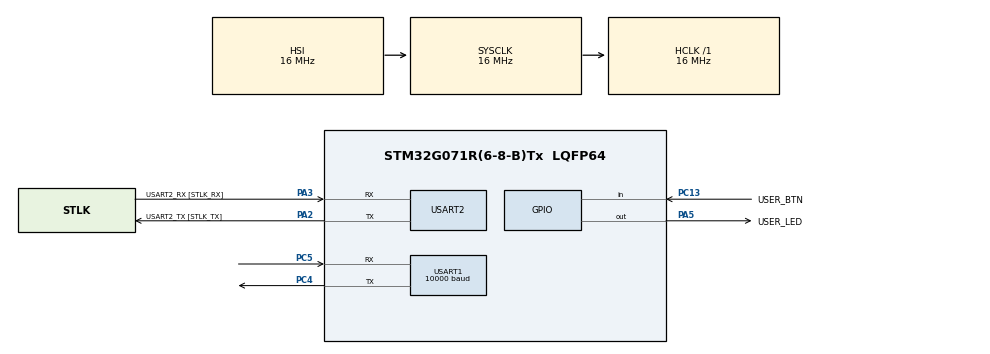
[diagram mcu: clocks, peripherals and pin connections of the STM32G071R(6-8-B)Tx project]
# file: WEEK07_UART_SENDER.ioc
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Mcu.Family=STM32G0
Mcu.Name=STM32G071R(6-8-B)Tx
Mcu.Package=LQFP64
PA13.GPIO_Label=TMS
PA13.Mode=Serial_Wire
PA13.Signal=SYS_SWDIO
PA14-BOOT0.GPIO_Label=TCK
PA14-BOOT0.Mode=Serial_Wire
PA14-BOOT0.Signal=SYS_SWCLK
PA2.GPIO_Label=USART2_TX [STLK_TX]
PA2.GPIO_PuPd=GPIO_PULLUP
PA2.Mode=Asynchronous
PA2.Signal=USART2_TX
PA3.GPIO_Label=USART2_RX [STLK_RX]
PA3.GPIO_PuPd=GPIO_PULLUP
PA3.Mode=Asynchronous
PA3.Signal=USART2_RX
PA5.GPIO_Label=USER_LED
PA5.GPIO_Speed=GPIO_SPEED_FREQ_HIGH
PA5.Signal=GPIO_Output
PC13.GPIO_Label=USER_BTN
PC13.Signal=GPIO_Input
PC14-OSC32_IN\ (PC14).Mode=LSE-External-Oscillator
PC14-OSC32_IN\ (PC14).Signal=RCC_OSC32_IN
PC15-OSC32_OUT\ (PC15).Mode=LSE-External-Oscillator
PC15-OSC32_OUT\ (PC15).Signal=RCC_OSC32_OUT
PC4.Mode=Asynchronous
PC4.Signal=USART1_TX
PC5.Mode=Asynchronous
PC5.Signal=USART1_RX
PF0-OSC_IN\ (PF0).GPIO_Label=MCO
PF0-OSC_IN\ (PF0).Mode=HSE-External-Clock-Source
PF0-OSC_IN\ (PF0).Signal=RCC_OSC_IN
ProjectManager.HeapSize=0x200
ProjectManager.StackSize=0x400
ProjectManager.TargetToolchain=STM32CubeIDE
RCC.AHBFreq_Value=16000000
RCC.CortexFreq_Value=16000000
RCC.EXTERNAL_CLOCK_VALUE=12288000
RCC.HCLKFreq_Value=16000000
RCC.HSE_VALUE=8000000
RCC.HSI_VALUE=16000000
RCC.SYSCLKFreq_VALUE=16000000
RCC.VCOOutputFreq_Value=128000000
USART1.BaudRate=10000
USART1.VirtualMode-Asynchronous=VM_ASYNC
USART2.VirtualMode-Asynchronous=VM_ASYNC
board=NUCLEO-G071RB

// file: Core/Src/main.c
/* USER CODE BEGIN Header */
/**
  ******************************************************************************
  * @file           : main.c
  * @brief          : Main program body
  ******************************************************************************
  * @attention
  *
  * Copyright (c) 2024 STMicroelectronics.
  * All rights reserved.
  *
  * This software is licensed under terms that can be found in the LICENSE file
  * in the root directory of this software component.
  * If no LICENSE file comes with this software, it is provided AS-IS.
  *
  ******************************************************************************
  */
/* USER CODE END Header */
#include "main.h"

UART_HandleTypeDef huart1;
UART_HandleTypeDef huart2;

void SystemClock_Config(void);
static void MX_GPIO_Init(void);
static void MX_USART2_UART_Init(void);
static void MX_USART1_UART_Init(void);

int main(void)
{

  /* MCU Configuration--------------------------------------------------------*/

  /* Reset of all peripherals, Initializes the Flash interface and the Systick. */
  HAL_Init();

  /* Configure the system clock */
  SystemClock_Config();

  /* Initialize all configured peripherals */
  MX_GPIO_Init();
  MX_USART2_UART_Init();
  MX_USART1_UART_Init();
  /* USER CODE BEGIN 2 */
  HAL_UART_Transmit(&huart2, "Start\r\n", 7, 1000);
  /* USER CODE END 2 */

  /* Infinite loop */
  while (1)
  {
	  unsigned char data[10] = "A"; // = 65 DEC , 0X41 , 0b01000001
	  while(HAL_GPIO_ReadPin(USER_BTN_GPIO_Port, USER_BTN_Pin) == 0){
		  HAL_UART_Transmit(&huart1, data, 1, 1000);
		  HAL_UART_Transmit(&huart2, data, 1, 1000);
		  data[0]++;
		  HAL_Delay(3000);
	  }
	  HAL_Delay(1000);
  }
}

void SystemClock_Config(void)
{
  RCC_OscInitTypeDef RCC_OscInitStruct = {0};
  RCC_ClkInitTypeDef RCC_ClkInitStruct = {0};

  /** Configure the main internal regulator output voltage
  */
  HAL_PWREx_ControlVoltageScaling(PWR_REGULATOR_VOLTAGE_SCALE1);

  /** Initializes the RCC Oscillators according to the specified parameters
  * in the RCC_OscInitTypeDef structure.
  */
  RCC_OscInitStruct.OscillatorType = RCC_OSCILLATORTYPE_HSI;
  RCC_OscInitStruct.HSIState = RCC_HSI_ON;
  RCC_OscInitStruct.HSIDiv = RCC_HSI_DIV1;
  RCC_OscInitStruct.HSICalibrationValue = RCC_HSICALIBRATION_DEFAULT;
  RCC_OscInitStruct.PLL.PLLState = RCC_PLL_NONE;
  if (HAL_RCC_OscConfig(&RCC_OscInitStruct) != HAL_OK)
  {
    Error_Handler();
  }

  /** Initializes the CPU, AHB and APB buses clocks
  */
  RCC_ClkInitStruct.ClockType = RCC_CLOCKTYPE_HCLK|RCC_CLOCKTYPE_SYSCLK
                              |RCC_CLOCKTYPE_PCLK1;
  RCC_ClkInitStruct.SYSCLKSource = RCC_SYSCLKSOURCE_HSI;
  RCC_ClkInitStruct.AHBCLKDivider = RCC_SYSCLK_DIV1;
  RCC_ClkInitStruct.APB1CLKDivider = RCC_HCLK_DIV1;

  if (HAL_RCC_ClockConfig(&RCC_ClkInitStruct, FLASH_LATENCY_0) != HAL_OK)
  {
    Error_Handler();
  }
}

static void MX_USART1_UART_Init(void)
{

  huart1.Instance = USART1;
  huart1.Init.BaudRate = 10000;
  huart1.Init.WordLength = UART_WORDLENGTH_8B;
  huart1.Init.StopBits = UART_STOPBITS_1;
  huart1.Init.Parity = UART_PARITY_NONE;
  huart1.Init.Mode = UART_MODE_TX_RX;
  huart1.Init.HwFlowCtl = UART_HWCONTROL_NONE;
  huart1.Init.OverSampling = UART_OVERSAMPLING_16;
  huart1.Init.OneBitSampling = UART_ONE_BIT_SAMPLE_DISABLE;
  huart1.Init.ClockPrescaler = UART_PRESCALER_DIV1;
  huart1.AdvancedInit.AdvFeatureInit = UART_ADVFEATURE_NO_INIT;
  if (HAL_UART_Init(&huart1) != HAL_OK)
  {
    Error_Handler();
  }
  if (HAL_UARTEx_SetTxFifoThreshold(&huart1, UART_TXFIFO_THRESHOLD_1_8) != HAL_OK)
  {
    Error_Handler();
  }
  if (HAL_UARTEx_SetRxFifoThreshold(&huart1, UART_RXFIFO_THRESHOLD_1_8) != HAL_OK)
  {
    Error_Handler();
  }
  if (HAL_UARTEx_DisableFifoMode(&huart1) != HAL_OK)
  {
    Error_Handler();
  }

}

static void MX_USART2_UART_Init(void)
{

  huart2.Instance = USART2;
  huart2.Init.BaudRate = 115200;
  huart2.Init.WordLength = UART_WORDLENGTH_8B;
  huart2.Init.StopBits = UART_STOPBITS_1;
  huart2.Init.Parity = UART_PARITY_NONE;
  huart2.Init.Mode = UART_MODE_TX_RX;
  huart2.Init.HwFlowCtl = UART_HWCONTROL_NONE;
  huart2.Init.OverSampling = UART_OVERSAMPLING_16;
  huart2.Init.OneBitSampling = UART_ONE_BIT_SAMPLE_DISABLE;
  huart2.Init.ClockPrescaler = UART_PRESCALER_DIV1;
  huart2.AdvancedInit.AdvFeatureInit = UART_ADVFEATURE_NO_INIT;
  if (HAL_UART_Init(&huart2) != HAL_OK)
  {
    Error_Handler();
  }
  if (HAL_UARTEx_SetTxFifoThreshold(&huart2, UART_TXFIFO_THRESHOLD_1_8) != HAL_OK)
  {
    Error_Handler();
  }
  if (HAL_UARTEx_SetRxFifoThreshold(&huart2, UART_RXFIFO_THRESHOLD_1_8) != HAL_OK)
  {
    Error_Handler();
  }
  if (HAL_UARTEx_DisableFifoMode(&huart2) != HAL_OK)
  {
    Error_Handler();
  }

}

static void MX_GPIO_Init(void)
{
  GPIO_InitTypeDef GPIO_InitStruct = {0};

  /* GPIO Ports Clock Enable */
  __HAL_RCC_GPIOC_CLK_ENABLE();
  __HAL_RCC_GPIOF_CLK_ENABLE();
  __HAL_RCC_GPIOA_CLK_ENABLE();

  /*Configure GPIO pin Output Level */
  HAL_GPIO_WritePin(USER_LED_GPIO_Port, USER_LED_Pin, GPIO_PIN_RESET);

  /*Configure GPIO pin : USER_BTN_Pin */
  GPIO_InitStruct.Pin = USER_BTN_Pin;
  GPIO_InitStruct.Mode = GPIO_MODE_INPUT;
  GPIO_InitStruct.Pull = GPIO_NOPULL;
  HAL_GPIO_Init(USER_BTN_GPIO_Port, &GPIO_InitStruct);

  /*Configure GPIO pin : USER_LED_Pin */
  GPIO_InitStruct.Pin = USER_LED_Pin;
  GPIO_InitStruct.Mode = GPIO_MODE_OUTPUT_PP;
  GPIO_InitStruct.Pull = GPIO_NOPULL;
  GPIO_InitStruct.Speed = GPIO_SPEED_FREQ_HIGH;
  HAL_GPIO_Init(USER_LED_GPIO_Port, &GPIO_InitStruct);

}

void Error_Handler(void)
{
  __disable_irq();
  while (1)
  {
  }
}
